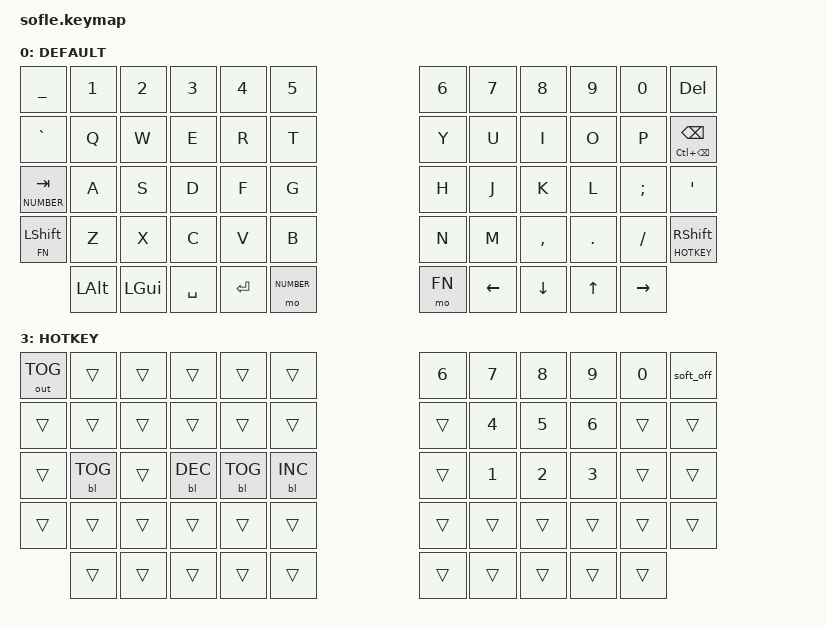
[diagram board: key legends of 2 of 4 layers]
/*
 * Copyright (c) 2023 The ZMK Contributors
 *
 * SPDX-License-Identifier: MIT
 */

#include <behaviors.dtsi>
#include <dt-bindings/zmk/keys.h>
#include <dt-bindings/zmk/bt.h>
#include <dt-bindings/zmk/outputs.h>
#include <dt-bindings/zmk/backlight.h>
#include <dt-bindings/zmk/input_transform.h>
#include <zephyr/dt-bindings/input/input-event-codes.h>

#define ZMK_POINTING_DEFAULT_SCRL_VAL 100
#include <dt-bindings/zmk/pointing.h>

// Helpful macros borrowed from AndrewMSHowe
#define ___ &trans

// Layer numbers for use by the keymap & macros

#define DEFAULT 0
#define NUMBER  1
#define FN  2
#define HOTKEY  3

/* Gesture shortcuts run on the central half after split input forwarding. */
/ {
    behaviors {
        browser_back: browser_back {
            compatible = "zmk,behavior-macro";
            #binding-cells = <0>;
            tap-ms = <30>;
            wait-ms = <0>;
            bindings = <&macro_tap &kp LG(LBKT)>;
        };
        browser_forward: browser_forward {
            compatible = "zmk,behavior-macro";
            #binding-cells = <0>;
            tap-ms = <30>;
            wait-ms = <0>;
            bindings = <&macro_tap &kp LG(RBKT)>;
        };
        mission_control: mission_control {
            compatible = "zmk,behavior-macro";
            #binding-cells = <0>;
            tap-ms = <30>;
            wait-ms = <0>;
            bindings = <&macro_tap &kp LC(UP)>;
        };
    };

    input_processors {
        sofle_pinch_modifier: sofle_pinch_modifier {
            compatible = "zmk,input-processor-behaviors";
            #input-processor-cells = <0>;
            codes = <INPUT_BTN_SELECT>;
            bindings = <&kp LGUI>;
        };
        sofle_gestures: sofle_gestures {
            compatible = "zmk,input-processor-behaviors";
            #input-processor-cells = <0>;
            codes = <INPUT_BTN_NORTH INPUT_BTN_SOUTH INPUT_BTN_WEST INPUT_BTN_EAST>;
            bindings = <&mission_control &none &browser_back &browser_forward>;
        };
    };
};

&tps43_listener {
    input-processors = <&sofle_pinch_modifier>, <&sofle_gestures>,
        <&zip_xy_transform (INPUT_TRANSFORM_XY_SWAP | INPUT_TRANSFORM_X_INVERT)>,
        <&zip_scroll_transform INPUT_TRANSFORM_XY_SWAP>;
};



/ {

    keymap {
        compatible = "zmk,keymap";

        windows_default_layer {
            label = "DEFAULT";
            bindings = <
// ╭───────────────┬───────────────┬───────────────┬───────────────┬───────────────┬───────────────╮                                 ╭───────────────┬───────────────┬───────────────┬───────────────┬───────────────┬───────────────╮
       &kp UNDER      &kp N1           &kp N2          &kp N3          &kp N4          &kp N5    /*|                                 |*/  &kp N6         &kp N7          &kp N8          &kp N9          &kp N0         &kp DEL
       &kp GRAVE      &kp Q            &kp W           &kp E           &kp R           &kp T     /*|                                 |*/  &kp Y          &kp U           &kp I           &kp O           &kp P          &mt LC(BSPC) BSPC
       &lt NUMBER TAB &kp A            &kp S           &kp D           &kp F           &kp G     /*├─────────────╮     ╭─────────────┤*/  &kp H          &kp J           &kp K           &kp L           &kp SEMI       &kp SQT
       &lt FN LSHIFT  &kp Z            &kp X           &kp C           &kp V           &kp B                                              &kp N          &kp M           &kp COMMA       &kp DOT         &kp FSLH       &lt HOTKEY RSHFT
                       &kp LALT         &kp LGUI        &kp SPACE        &kp ENTER       &mo NUMBER                                             &mo FN         &kp LEFT       &kp DOWN        &kp UP          &kp RIGHT
            >;
        };

 

        windows_symbols_layer {
            label = "NUMBER";
            bindings = <
// ╭───────────────┬───────────────┬───────────────┬───────────────┬───────────────┬───────────────╮                                 ╭───────────────┬───────────────┬───────────────┬───────────────┬───────────────┬───────────────╮
       &kp UNDER       &kp N1          &kp N2          &kp N3          &kp N4          &kp N5    /*|                                 |*/  &kp N6         &kp N7          &kp N8          &kp N9          &kp N0          &kp DEL
       ___             &kp EXCL        &kp AT          &kp HASH        &kp DLLR        &kp PRCNT /*├─────────────╮     ╭─────────────┤*/  &kp CARET      &kp AMPERSAND   &kp STAR        &kp LPAR        &kp RPAR        &kp MINUS
       ___             &kp LG(DOT)     &kp LEFT_BRACE  &kp RIGHT_BRACE &kp PIPE        &kp EQUAL                                          &kp PRCNT      &kp PLUS        &kp LBKT        &kp RBKT        &kp BACKSLASH   ___
                       ___             ___             ___             ___             ___                                              ___             ___             ___             ___             ___
                       ___             ___             ___             ___             ___                                              ___             ___             ___             ___             ___
            >;
        };

        numpad_layer {
            label = "FN";
            
            bindings = <
// ╭───────────────┬───────────────┬───────────────┬───────────────┬───────────────┬───────────────╮                                 ╭───────────────┬───────────────┬───────────────┬───────────────┬───────────────┬───────────────╮
       ___             &kp N1          &kp N2          &kp N3          &kp N4          &kp N5    /*|                                 |*/    &kp N6         &kp N7          &kp N8          &kp N9          &kp N0          ___ 
       ___             &kp EXCL        &kp AT          &kp HASH        &kp DLLR        &kp PRCNT /*├─────────────╮     ╭─────────────┤*/  &kp CARET      &kp N4          &kp N5          &mt LPAR N6     &mt RPAR PLUS   &kp MINUS
       ___             ___             &kp LEFT_BRACE  &kp RIGHT_BRACE &kp PIPE        &kp EQUAL                                          &kp PRCNT      &kp N1          &mt COMMA N2    &mt DOT N3      &kp KP_DIVIDE   &kp KP_MULTIPLY
       ___             ___             ___             ___             ___             ___                                              ___             ___             ___             ___             ___             ___
       ___             ___             ___             ___             ___             ___                                              ___             ___             ___             ___             ___             ___
            >;
      };



      settings_layer {
            label = "HOTKEY";
            bindings = <
// ╭───────────────┬───────────────┬───────────────┬───────────────┬───────────────┬────────────────╮                                 ╭───────────────┬───────────────┬───────────────┬───────────────┬───────────────┬───────────────╮
      &out OUT_TOG     ___     ___      ___     ___      ___ /*|                                 |*/   &kp N6         &kp N7          &kp N8          &kp N9          &kp N0          &soft_off
      ___              ___             ___             ___             ___             ___        /*├─────────────╮     ╭─────────────┤*/   ___            &kp N4          &kp N5          &kp N6          ___             ___
      ___              &bl BL_TOG      ___   &bl BL_DEC      &bl BL_TOG      &bl BL_INC                                           ___            &kp N1          &kp N2          &kp N3          ___             ___
                        ___             ___             ___             ___             ___                                            ___            ___             ___             ___             ___
       ___              ___             ___             ___             ___             ___                                            ___            ___             ___             ___             ___             ___
            >;
        };

    

    };

};
